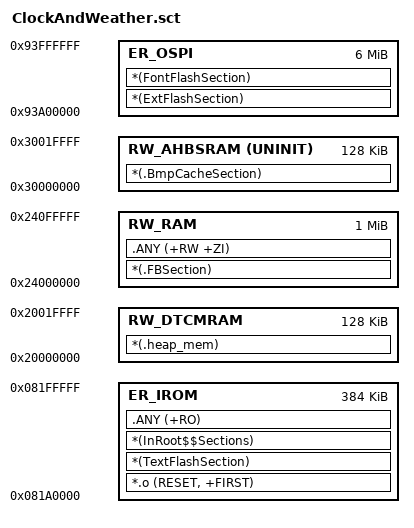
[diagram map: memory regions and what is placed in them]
; *************************************************************
; *** Scatter-Loading Description File generated by uVision ***
; *************************************************************

LR_IROM 0x081A0000 0x60000  {    ; load region size_region
  ER_IROM 0x081A0000  0x60000{
   *.o (RESET, +FIRST)
   *(TextFlashSection)
    *(InRoot$$Sections)
      .ANY (+RO)     
 }
                
 RW_DTCMRAM 0x20000000  0x00020000 { 
  *(.heap_mem)
  
  }
  RW_RAM 0x24000000 0x100000 {
  *(.FBSection)
   .ANY (+RW +ZI)
  }
}

LR_OSPI 0x93A00000 0x600000 {    
 ER_OSPI 0x93A00000 0x600000  {	
  	*(ExtFlashSection)
	 *(FontFlashSection) 
	}
RW_AHBSRAM 0x30000000 UNINIT 0x20000 { ; RW data
  *(.BmpCacheSection)
  	}
}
